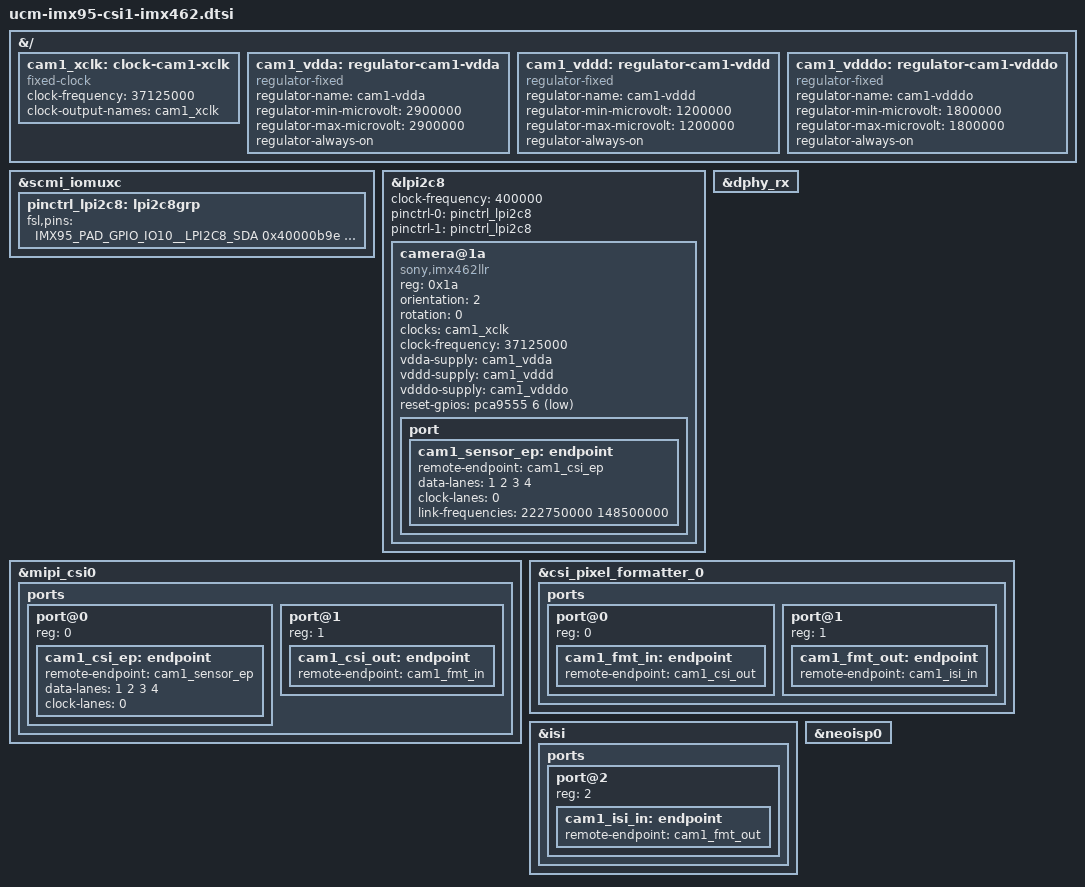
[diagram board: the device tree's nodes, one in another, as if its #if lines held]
// SPDX-License-Identifier: (GPL-2.0-or-later OR MIT)
// SPDX-FileCopyrightText: 2026 UAB Kurokesu
/*
 * Sony IMX462 on CSI1 (EB-EVCAMRPI J1), UCM-iMX95.
 * Included by csi1 .dtso wrappers. Define CAM_MONO for mono variant.
 */

&{/} {
	cam1_xclk: clock-cam1-xclk {
		compatible = "fixed-clock";
		#clock-cells = <0>;
		clock-frequency = <37125000>;
		clock-output-names = "cam1_xclk";
	};

	cam1_vdda: regulator-cam1-vdda {
		compatible = "regulator-fixed";
		regulator-name = "cam1-vdda";
		regulator-min-microvolt = <2900000>;
		regulator-max-microvolt = <2900000>;
		regulator-always-on;
	};

	cam1_vddd: regulator-cam1-vddd {
		compatible = "regulator-fixed";
		regulator-name = "cam1-vddd";
		regulator-min-microvolt = <1200000>;
		regulator-max-microvolt = <1200000>;
		regulator-always-on;
	};

	cam1_vdddo: regulator-cam1-vdddo {
		compatible = "regulator-fixed";
		regulator-name = "cam1-vdddo";
		regulator-min-microvolt = <1800000>;
		regulator-max-microvolt = <1800000>;
		regulator-always-on;
	};
};

&scmi_iomuxc {
	pinctrl_lpi2c8: lpi2c8grp {
		fsl,pins = <
			IMX95_PAD_GPIO_IO10__LPI2C8_SDA			0x40000b9e
			IMX95_PAD_GPIO_IO11__LPI2C8_SCL			0x40000b9e
		>;
	};
};

&lpi2c8 {
	#address-cells = <1>;
	#size-cells = <0>;
	clock-frequency = <400000>;
	pinctrl-names = "default", "sleep";
	pinctrl-0 = <&pinctrl_lpi2c8>;
	pinctrl-1 = <&pinctrl_lpi2c8>;
	status = "okay";

	camera@1a {
#ifdef CAM_MONO
		compatible = "sony,imx462llr";
#else
		compatible = "sony,imx462lqr";
#endif
		reg = <0x1a>;
		status = "okay";

		orientation = <2>;
		rotation = <0>;

		clocks = <&cam1_xclk>;
		clock-names = "xclk";
		clock-frequency = <37125000>;

		vdda-supply = <&cam1_vdda>;
		vddd-supply = <&cam1_vddd>;
		vdddo-supply = <&cam1_vdddo>;

		reset-gpios = <&pca9555 6 GPIO_ACTIVE_LOW>;

		port {
			cam1_sensor_ep: endpoint {
				remote-endpoint = <&cam1_csi_ep>;
				data-lanes = <1 2 3 4>;
				clock-lanes = <0>;
				link-frequencies = /bits/ 64 <222750000 148500000>;
			};
		};
	};
};

&dphy_rx {
	status = "okay";
};

&mipi_csi0 {
	status = "okay";

	ports {
		#address-cells = <1>;
		#size-cells = <0>;

		port@0 {
			reg = <0>;
			cam1_csi_ep: endpoint {
				remote-endpoint = <&cam1_sensor_ep>;
				data-lanes = <1 2 3 4>;
				clock-lanes = <0>;
			};
		};

		port@1 {
			reg = <1>;
			cam1_csi_out: endpoint {
				remote-endpoint = <&cam1_fmt_in>;
			};
		};
	};
};

&csi_pixel_formatter_0 {
	status = "okay";

	ports {
		#address-cells = <1>;
		#size-cells = <0>;

		port@0 {
			reg = <0>;
			cam1_fmt_in: endpoint {
				remote-endpoint = <&cam1_csi_out>;
			};
		};

		port@1 {
			reg = <1>;
			cam1_fmt_out: endpoint {
				remote-endpoint = <&cam1_isi_in>;
			};
		};
	};
};

&isi {
	status = "okay";

	ports {
		#address-cells = <1>;
		#size-cells = <0>;

		port@2 {
			reg = <2>;
			cam1_isi_in: endpoint {
				remote-endpoint = <&cam1_fmt_out>;
			};
		};
	};
};

&neoisp0 {
	status = "okay";
};
